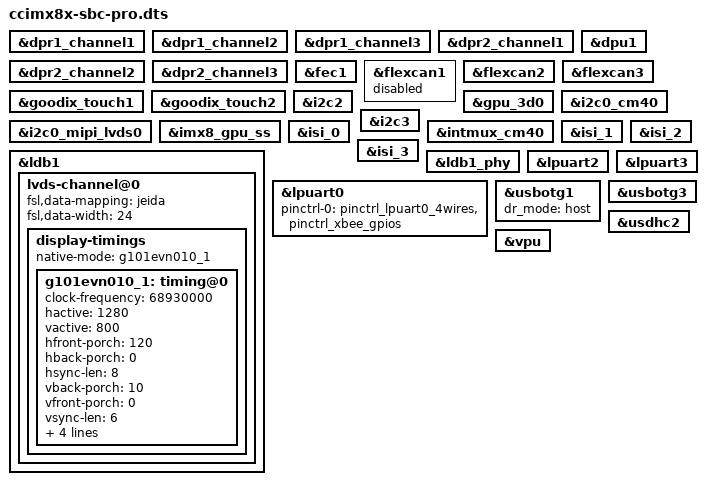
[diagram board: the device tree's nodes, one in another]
/*
 * Copyright 2018, Digi International Inc.
 *
 * Permission to use, copy, modify, and/or distribute this software for any
 * purpose with or without fee is hereby granted, provided that the above
 * copyright notice and this permission notice appear in all copies.
 * THE SOFTWARE IS PROVIDED "AS IS" AND THE AUTHOR DISCLAIMS ALL WARRANTIES
 * WITH REGARD TO THIS SOFTWARE INCLUDING ALL IMPLIED WARRANTIES OF
 * MERCHANTABILITY AND FITNESS. IN NO EVENT SHALL THE AUTHOR BE LIABLE FOR
 * ANY SPECIAL, DIRECT, INDIRECT, OR CONSEQUENTIAL DAMAGES OR ANY DAMAGES
 * WHATSOEVER RESULTING FROM LOSS OF USE, DATA OR PROFITS, WHETHER IN AN
 * ACTION OF CONTRACT, NEGLIGENCE OR OTHER TORTIOUS ACTION, ARISING OUT OF
 * OR IN CONNECTION WITH THE USE OR PERFORMANCE OF THIS SOFTWARE.
 */

/dts-v1/;

/* i.MX8QXP CPU */
#include "../freescale/fsl-imx8qxp.dtsi"
/* Digi ConnectCore 8X (non-WiFi variant) */
#include "ccimx8x.dtsi"
/* Digi ConnectCore 8X SBC Pro */
#include "ccimx8x-sbc-pro.dtsi"

&dpr1_channel1 {
	status = "okay";
};

&dpr1_channel2 {
	status = "okay";
};

&dpr1_channel3 {
	status = "okay";
};

&dpr2_channel1 {
	status = "okay";
};

&dpr2_channel2 {
	status = "okay";
};

&dpr2_channel3 {
	status = "okay";
};

&dpu1 {
	status = "okay";
};

&fec1 {
	status = "okay";
};

/*
 * CAN1 port conflicts with LPUART0 RTS/CTS lines.
 * Before enabling the port you need to configure
 * lpuart0 node as 2 wires.
 */
&flexcan1 {
	status = "disabled";
};

/* CAN2 */
&flexcan2 {
	status = "okay";
};

/* CAN3 */
&flexcan3 {
	status = "okay";
};

/*
 * On the CC8X SBC, an inconsistent reset sequence makes
 * the Goodix display's touch controller respond to two I2C
 * addresses: 0x14 and 0x5D. To make sure the touchscreen
 * works every time, the touch controller's description must
 * be duplicated for both addresses.
 */
&goodix_touch1 {
	status = "okay";
};

&goodix_touch2 {
	status = "okay";
};

&gpu_3d0 {
	status = "okay";
};

&i2c0_cm40 {
	status = "okay";
};

/* I2C2 available on Raspberry Pi expansion header */
&i2c2 {
	status = "okay";
};

/* I2C3 available on Raspberry Pi expansion header */
&i2c3 {
	status = "okay";
};

&i2c0_mipi_lvds0 {
	status = "okay";
};

&imx8_gpu_ss {
	status = "okay";
};

&intmux_cm40 {
	status = "okay";
};

&isi_0 {
	status = "okay";
};

&isi_1 {
	status = "okay";
};

&isi_2 {
	status = "okay";
};

&isi_3 {
	status = "okay";
};

&ldb1 {
	status = "okay";

	lvds-channel@0 {
		fsl,data-mapping = "jeida";
		fsl,data-width = <24>;
		status = "okay";

		display-timings {
			native-mode = <&g101evn010_1>;

			/* AUO G101EVN01.0 */
			g101evn010_1: timing@0 {
				clock-frequency = <68930000>;
				hactive = <1280>;
				vactive = <800>;
				hfront-porch = <120>;
				hback-porch = <0>;
				hsync-len = <8>;
				vback-porch = <10>;
				vfront-porch = <0>;
				vsync-len = <6>;
				hsync-active = <1>;
				vsync-active = <1>;
				de-active = <1>;
				pixelclk-active = <0>;
			};
		};
	};
};

&ldb1_phy {
	status = "okay";
};

/* LPUART0 on XBee socket */
&lpuart0 {
	/* RTS/CTS lines multiplexed with CAN1 */
	pinctrl-0 = <&pinctrl_lpuart0_4wires>, <&pinctrl_xbee_gpios>;
	/* Comment the line above and uncomment the next one to use 2-wires */
	//pinctrl-0 = <&pinctrl_lpuart0_2wires>, <&pinctrl_xbee_gpios>;
	status = "okay";
};

/* Console */
&lpuart2 {
	status = "okay";
};

/* LPUART3 on expansion header */
&lpuart3 {
	status = "okay";
};

/*
 * Uncomment to enable MCA ADC channels on Rasberry Pi Expansion connector:
 *  - MCA_IO1 (channel 1)
 *  - MCA_IO2 (channel 2)
 *  - MCA_IO3 (channel 3)
 *  - MCA_IO4 (channel 4)
 *  - MCA_IO5 (channel 5)
 *  - MCA_IO6 (channel 6)
 *  - MCA_IO7 (channel 7)
 *  - MCA_IO8 (channel 8)
 * Edit adc-ch-list to include the ADC channels that you want to enable.
 */
// &mca_adc {
//	digi,adc-ch-list = <1 2 3 4 5 6 7 8>;
//	digi,adc-vref = <3000000>;
// };

&usbotg1 {
	/*
	 * To configure this USB port as a device set dr_mode to "otg";
	 * to configure it as a host set to "host" instead.
	 */
	dr_mode = "host";
	status = "okay";
};

&usbotg3 {
	status = "okay";
};

/* Micro SD card */
&usdhc2 {
	status = "okay";
};

&vpu {
	status = "okay";
};
